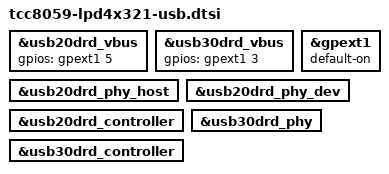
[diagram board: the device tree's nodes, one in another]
// SPDX-License-Identifier: (GPL-2.0-or-later OR MIT)
/*
 * Copyright (C) Telechips Inc.
 */

&usb20drd_vbus {
	gpios = <&gpext1 5 0x0>;
	status = "okay";
};

&usb30drd_vbus {
	gpios = <&gpext1 3 0x0>;
	status = "okay";
};

&gpext1 {
	default-on;
};

&usb20drd_phy_host {
	status = "okay";
};

&usb20drd_phy_dev {
	status = "okay";
};

&usb20drd_controller {
	status = "okay";
};

&usb30drd_phy {
	status = "okay";
};

&usb30drd_controller {
	status = "okay";
};
